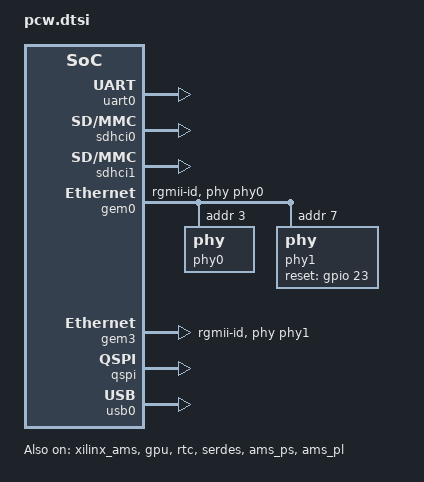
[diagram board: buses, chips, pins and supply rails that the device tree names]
/*
 * CAUTION: This file is automatically generated by Xilinx.
 * Version: XSCT 2020.2
 * Today is: Fri Feb 19 11:42:01 2021
 */


&fclk0 {
	status = "okay";
};
&gic {
	num_cpus = <2>;
	num_interrupts = <96>;
};
&lpd_dma_chan1 {
	status = "okay";
};
&lpd_dma_chan2 {
	status = "okay";
};
&lpd_dma_chan3 {
	status = "okay";
};
&lpd_dma_chan4 {
	status = "okay";
};
&lpd_dma_chan5 {
	status = "okay";
};
&lpd_dma_chan6 {
	status = "okay";
};
&lpd_dma_chan7 {
	status = "okay";
};
&lpd_dma_chan8 {
	status = "okay";
};
&xilinx_ams {
	status = "okay";
};
&fpd_dma_chan1 {
	status = "okay";
};
&fpd_dma_chan2 {
	status = "okay";
};
&fpd_dma_chan3 {
	status = "okay";
};
&fpd_dma_chan4 {
	status = "okay";
};
&fpd_dma_chan5 {
	status = "okay";
};
&fpd_dma_chan6 {
	status = "okay";
};
&fpd_dma_chan7 {
	status = "okay";
};
&fpd_dma_chan8 {
	status = "okay";
};
&gpio {
	emio-gpio-width = <32>;
	gpio-mask-high = <0x0>;
	gpio-mask-low = <0x5600>;
	status = "okay";
};
&gpu {
	status = "okay";
	xlnx,tz-nonsecure = <0x1>;
};
&rtc {
	status = "okay";
};
&serdes {
	status = "okay";
};
&uart0 {
	cts-override ;
	device_type = "serial";
	port-number = <0>;
	status = "okay";
	u-boot,dm-pre-reloc ;
};
&ams_ps {
	status = "okay";
};
&ams_pl {
	status = "okay";
};

&sdhci0 {
	clock-frequency = <199998001>;
	status = "okay";
	xlnx,mio_bank = <0x0>;
	nvmem-cells = <&soc_revision>;
	nvmem-cell-names = "soc_revision";
	#clock-cells = <1>;
	clock-output-names = "clk_out_sd0", "clk_in_sd0";
};
&sdhci1 {
	clock-frequency = <199998001>;
	status = "okay";
	disable-wp;
	no-1-8-v;
	xlnx,mio_bank = <0x1>;
	nvmem-cells = <&soc_revision>;
	nvmem-cell-names = "soc_revision";
	#clock-cells = <1>;
	clock-output-names = "clk_out_sd1", "clk_in_sd1";
};

&gem0 {
	status = "okay";
	phy-mode = "rgmii-id";
	phy-handle = <&phy0>;
        /delete-property/ xlnx,ptp-enet-clock;
	phy0: phy@3 {
		reg = <3>;

		txc-skew-ps = <1800>;
		txen-skew-ps = <420>;

		txd0-skew-ps = <420>;
		txd1-skew-ps = <420>;
		txd2-skew-ps = <420>;
		txd3-skew-ps = <420>;

		rxc-skew-ps = <900>;
		rxdv-skew-ps = <420>;

		rxd0-skew-ps = <420>;
		rxd1-skew-ps = <420>;
		rxd2-skew-ps = <420>;
		rxd3-skew-ps = <420>;	
	};
	phy1: phy@7 {
		reg = <7>;

		reset-gpios = <&gpio 23 0>;

		txc-skew-ps = <1800>;
		txen-skew-ps = <420>;

		txd0-skew-ps = <420>;
		txd1-skew-ps = <420>;
		txd2-skew-ps = <420>;
		txd3-skew-ps = <420>;

		rxc-skew-ps = <900>;
		rxdv-skew-ps = <420>;

		rxd0-skew-ps = <420>;
		rxd1-skew-ps = <420>;
		rxd2-skew-ps = <420>;
		rxd3-skew-ps = <420>;	
	};
};
&gem3 {
	status = "okay";
	phy-mode = "rgmii-id";
	phy-handle = <&phy1>;
};
&i2c0 {
	status = "disabled";
	clock-frequency = <100000>;
	atsha204a@64 {
		compatible = "atmel,atsha204a";
		reg = <0x64>;
	};
};
&qspi {
	is-dual = <0>;
	num-cs = <1>;
	spi-rx-bus-width = <4>;
	spi-tx-bus-width = <4>;
	status = "okay";
};
/* ULPI SMSC USB3320 */
&usb0 {
	status = "okay";
};

